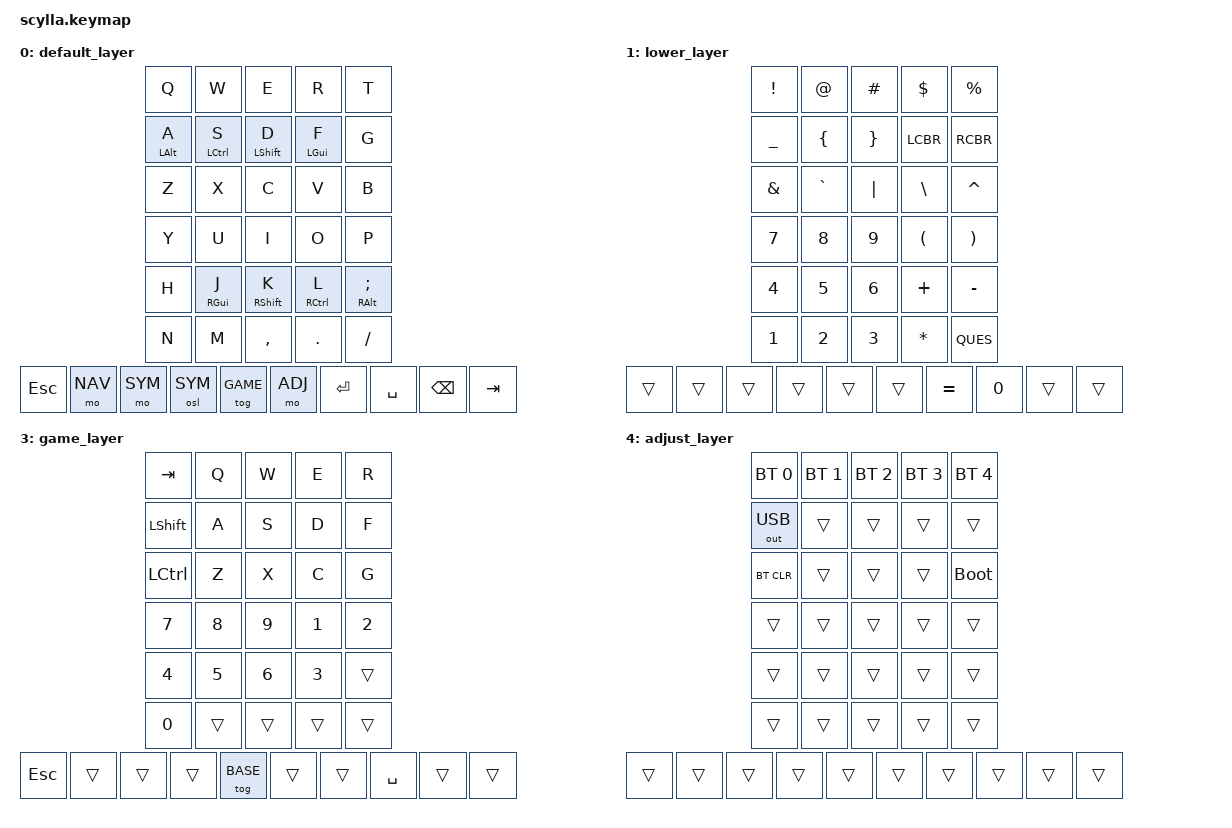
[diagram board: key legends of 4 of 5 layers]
/*
 * Keymap Completo para Scylla (5x3 + 5 Polegares)
 * Otimizado para: Dev Android Nativo, Vim, Jogos.
 *
 * Features:
 * - Home Row Mods (HRM)
 * - Camada de Símbolos [SYM] com Numpad
 * - Camada de Navegação [NAV] com setas e atalhos IDE
 * - Camada de Jogo [GAME] sem HRM
 * - One-Shot Layer (OSL) para [SYM]
 */

#include <behaviors.dtsi>
#include <dt-bindings/zmk/keys.h>
#include <dt-bindings/zmk/bt.h>
#include <dt-bindings/zmk/outputs.h>

/* --- Definição das Camadas --- */
#define BASE 0 // Camada principal (Alfas, HRM)
#define SYM 1  // Camada de Símbolos (para programar)
#define NAV 2  // Camada de Navegação (Setas, IDE)
#define GAME 3 // Camada de Jogo (WASD, sem HRM)
#define ADJ 4  // Camada de Ajustes (BT, USB, Reset)

/ {
    /* --- Comportamentos Especiais (HRM e OSL) --- */
    behaviors {
        
        // Comportamento genérico de Home Row Mod (Segura = Mod, Toca = Tecla)
        hm: behavior_hold_tap {
            compatible = "zmk,behavior-hold-tap";
            label = "HOME_ROW_MOD";
            #binding-cells = <2>;
            tapping-term-ms = <220>; // Ajuste este valor se necessário
            flavor = "tap-preferred"; 
            bindings = <&kp>, <&kp>;
        };

        // Comportamento genérico de One-Shot Layer (OSL)
        osl: behavior_osl {
            compatible = "zmk,behavior-hold-tap";
            label = "ONE_SHOT_LAYER";
            #binding-cells = <1>;
            tapping-term-ms = <200>;
            flavor = "tap-preferred";
            bindings = <&osl>; 
        };
    };

    /* --- Mapeamento das Teclas --- */
    keymap {
        compatible = "zmk,keymap";

        /* --- LAYER 0: [BASE] ---
         * Foco: Digitação, comandos normais do Vim (HJKL), Home Row Mods.
         */
        default_layer {
            // Esta é a camada BASE (índice 0)
            bindings = <
            // 5x3 Bloco Principal (Esquerda)
            &kp Q         &kp W         &kp E         &kp R         &kp T
            &hm LALT A    &hm LCTRL S   &hm LSHIFT D  &hm LGUI F    &kp G
            &kp Z         &kp X         &kp C         &kp V         &kp B
            // 5x3 Bloco Principal (Direita)
                                        &kp Y     &kp U     &kp I         &kp O         &kp P
                                        &kp H     &hm RGUI J  &hm RSHIFT K  &hm RCTRL L   &hm RALT SEMI
                                        &kp N     &kp M     &kp COMMA     &kp DOT       &kp FSLH
            // Polegares (5+5, assumindo layout 3+2 do Scylla)
            // Esquerda (Interno)  Esquerda (Externo)     Direita (Interno)     Direita (Externo)
            &kp ESC &mo NAV &mo SYM   &osl SYM &tog GAME    &mo ADJ &kp RET &kp SPACE   &kp BSPC &kp TAB
            >;
        };

        /* --- LAYER 1: [SYM] ---
         * Foco: Símbolos de programação, Numpad. (Segurando ou tocando o polegar SYM)
         * NENHUMA tecla aqui precisa de Shift.
         */
        lower_layer {
            // Esta é a camada SYM (índice 1)
            bindings = <
            // 5x3 Bloco Principal (Esquerda)
            &kp EXCL    &kp AT      &kp HASH    &kp DLLR    &kp PRCNT
            &kp UNDER   &kp LBRC    &kp RBRC    &kp LCBR    &kp RCBR
            &kp AMPS    &kp GRAVE   &kp PIPE    &kp BSLH    &kp CARET
            // 5x3 Bloco Principal (Direita)
                                        &kp N7    &kp N8    &kp N9    &kp LPAR    &kp RPAR
                                        &kp N4    &kp N5    &kp N6    &kp PLUS    &kp MINUS
                                        &kp N1    &kp N2    &kp N3    &kp ASTRK   &kp QUES
            // Polegares (Space vira 0, Enter vira =)
            &trans &trans &trans   &trans &trans     &trans &kp EQUAL &kp N0   &trans &trans
            >;
        };

        /* --- LAYER 2: [NAV] ---
         * Foco: Navegação, F-Keys, Atalhos da IDE. (Segurando o polegar NAV)
         */
        raise_layer {
            // Esta é a camada NAV (índice 2)
            bindings = <
            // 5x3 Bloco Principal (Esquerda)
            &kp F1                 &kp F2                 &kp F3                 &kp F4                 &kp F5
            &kp LCTRL B            &kp LALT F7            &kp LCTRL N            &kp LCTRL LALT L       &trans
            &kp F11                &kp F12                &kp C_VOL_DN           &kp C_VOL_UP           &kp C_MUTE
            // 5x3 Bloco Principal (Direita)
                                        &kp HOME    &kp PG_DN   &kp PG_UP   &kp END     &kp DEL
                                        &kp LEFT    &kp DOWN    &kp UP      &kp RIGHT   &trans
                                        &trans      &trans      &trans      &trans      &trans
            // Polegares
            &trans &trans &trans   &trans &trans     &trans &trans &trans   &trans &trans
            >;
        };

        /* --- LAYER 3: [GAME] ---
         * Foco: Jogos. Layout "burro" sem HRM. (Ativado/Desativado tocando o polegar GAME)
         */
        game_layer {
            // Esta é a camada GAME (índice 3)
            bindings = <
            // 5x3 Bloco Principal (Esquerda)
            &kp TAB     &kp Q       &kp W       &kp E       &kp R
            &kp LSHIFT  &kp A       &kp S       &kp D       &kp F
            &kp LCTRL   &kp Z       &kp X       &kp C       &kp G
            // 5x3 Bloco Principal (Direita)
                                        &kp N7    &kp N8    &kp N9    &kp N1      &kp N2
                                        &kp N4    &kp N5    &kp N6    &kp N3      &trans
                                        &kp N0    &trans    &trans    &trans      &trans
            // Polegares (Tecla GAME vira o botão de voltar para BASE)
            &kp ESC &trans &trans   &trans &tog BASE    &trans &trans &kp SPACE   &trans &trans
            >;
        };

        /* --- LAYER 4: [ADJ] ---
         * Foco: Ajustes de sistema, Bluetooth, Reset. (Segurando o polegar ADJ)
         */
        adjust_layer {
            // Esta é a camada ADJ (índice 4)
            bindings = <
            // 5x3 Bloco Principal (Esquerda)
            &bt BT_SEL 0  &bt BT_SEL 1  &bt BT_SEL 2  &bt BT_SEL 3  &bt BT_SEL 4
            &out OUT_USB  &trans        &trans        &trans        &trans
            &bt BT_CLR    &trans        &trans        &trans        &bootloader
            // 5x3 Bloco Principal (Direita)
                                        &trans    &trans    &trans    &trans    &trans
                                        &trans    &trans    &trans    &trans    &trans
                                        &trans    &trans    &trans    &trans    &trans
            // Polegares
            &trans &trans &trans   &trans &trans     &trans &trans &trans   &trans &trans
            >;
        };

    }; // Fim do keymap
}; // Fim do arquivo
